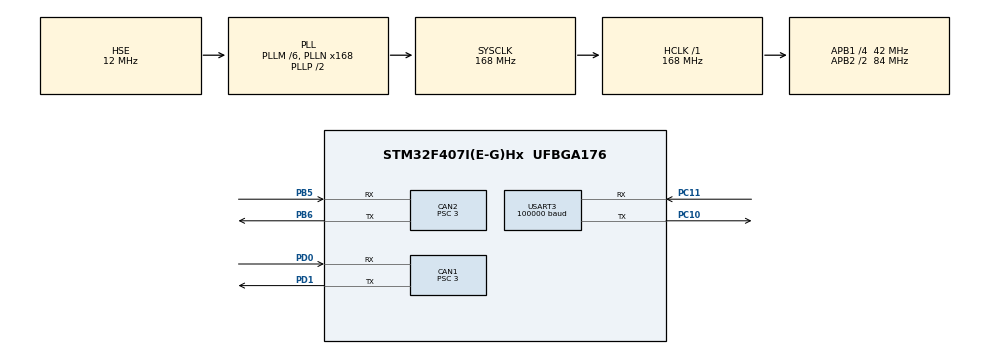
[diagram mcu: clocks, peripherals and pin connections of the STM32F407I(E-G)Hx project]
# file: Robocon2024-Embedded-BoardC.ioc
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CAN1.BS1=CAN_BS1_10TQ
CAN1.BS2=CAN_BS2_3TQ
CAN1.CalculateBaudRate=1000000
CAN1.CalculateTimeBit=1000
CAN1.CalculateTimeQuantum=71.42857142857143
CAN1.Prescaler=3
CAN2.BS1=CAN_BS1_10TQ
CAN2.BS2=CAN_BS2_3TQ
CAN2.CalculateBaudRate=1000000
CAN2.CalculateTimeBit=1000
CAN2.CalculateTimeQuantum=71.42857142857143
CAN2.Prescaler=3
Dma.Request0=USART3_RX
Dma.USART3_RX.0.Direction=DMA_PERIPH_TO_MEMORY
Dma.USART3_RX.0.FIFOMode=DMA_FIFOMODE_DISABLE
Dma.USART3_RX.0.Instance=DMA1_Stream1
Dma.USART3_RX.0.MemDataAlignment=DMA_MDATAALIGN_BYTE
Dma.USART3_RX.0.MemInc=DMA_MINC_ENABLE
Dma.USART3_RX.0.Mode=DMA_NORMAL
Dma.USART3_RX.0.PeriphDataAlignment=DMA_PDATAALIGN_BYTE
Dma.USART3_RX.0.PeriphInc=DMA_PINC_DISABLE
Dma.USART3_RX.0.Priority=DMA_PRIORITY_LOW
FREERTOS.Tasks01=workerTask,8,256,worker_task,As weak,NULL,Static,defaultTaskBuffer,defaultTaskControlBlock
FREERTOS.configENABLE_FPU=1
FREERTOS.configMINIMAL_STACK_SIZE=256
FREERTOS.configRECORD_STACK_HIGH_ADDRESS=1
Mcu.Family=STM32F4
Mcu.Name=STM32F407I(E-G)Hx
Mcu.Package=UFBGA176
NVIC.CAN1_RX0_IRQn=true\:5\:0\:false\:false\:true\:true\:true\:true\:true
NVIC.CAN1_RX1_IRQn=true\:5\:0\:false\:false\:true\:true\:true\:true\:true
NVIC.CAN1_SCE_IRQn=true\:5\:0\:false\:false\:true\:true\:true\:true\:true
NVIC.CAN1_TX_IRQn=true\:5\:0\:false\:false\:true\:true\:true\:true\:true
NVIC.DMA1_Stream1_IRQn=true\:5\:0\:false\:false\:true\:true\:false\:true\:true
NVIC.HASH_RNG_IRQn=true\:5\:0\:false\:false\:true\:true\:true\:true\:true
NVIC.PriorityGroup=NVIC_PRIORITYGROUP_4
NVIC.TIM1_BRK_TIM9_IRQn=true\:5\:0\:false\:false\:true\:true\:true\:false\:true
NVIC.TIM6_DAC_IRQn=true\:0\:0\:true\:false\:true\:false\:false\:true\:true
NVIC.TIM8_BRK_TIM12_IRQn=true\:5\:0\:false\:false\:true\:true\:true\:false\:true
NVIC.TimeBase=TIM6_DAC_IRQn
NVIC.TimeBaseIP=TIM6
NVIC.USART3_IRQn=true\:5\:0\:false\:false\:true\:true\:true\:true\:true
PA13.Mode=Serial_Wire
PA13.Signal=SYS_JTMS-SWDIO
PA14.Mode=Serial_Wire
PA14.Signal=SYS_JTCK-SWCLK
PB5.Mode=CAN_Activate
PB5.Signal=CAN2_RX
PB6.Mode=CAN_Activate
PB6.Signal=CAN2_TX
PC10.Mode=Asynchronous
PC10.Signal=USART3_TX
PC11.Mode=Asynchronous
PC11.Signal=USART3_RX
PD0.Mode=CAN_Activate
PD0.Signal=CAN1_RX
PD1.Mode=CAN_Activate
PD1.Signal=CAN1_TX
PH0-OSC_IN.Mode=HSE-External-Oscillator
PH0-OSC_IN.Signal=RCC_OSC_IN
PH1-OSC_OUT.Mode=HSE-External-Oscillator
PH1-OSC_OUT.Signal=RCC_OSC_OUT
ProjectManager.HeapSize=0x200
ProjectManager.StackSize=0x400
ProjectManager.TargetToolchain=Makefile
RCC.48MHZClocksFreq_Value=48000000
RCC.AHBFreq_Value=168000000
RCC.APB1CLKDivider=RCC_HCLK_DIV4
RCC.APB1Freq_Value=42000000
RCC.APB1TimFreq_Value=84000000
RCC.APB2CLKDivider=RCC_HCLK_DIV2
RCC.APB2Freq_Value=84000000
RCC.APB2TimFreq_Value=168000000
RCC.CortexFreq_Value=168000000
RCC.HCLKFreq_Value=168000000
RCC.HSE_VALUE=12000000
RCC.HSI_VALUE=16000000
RCC.LSE_VALUE=32768
RCC.PLLM=6
RCC.PLLN=168
RCC.PLLQ=7
RCC.PLLSourceVirtual=RCC_PLLSOURCE_HSE
RCC.SYSCLKFreq_VALUE=168000000
RCC.SYSCLKSource=RCC_SYSCLKSOURCE_PLLCLK
RCC.VCOOutputFreq_Value=336000000
TIM12.Channel-Output\ Compare1\ No\ Output=TIM_CHANNEL_1
TIM12.Channel-Output\ Compare2\ No\ Output=TIM_CHANNEL_2
TIM12.Prescaler=83
TIM9.AutoReloadPreload=TIM_AUTORELOAD_PRELOAD_DISABLE
TIM9.Channel-Output\ Compare1\ No\ Output=TIM_CHANNEL_1
TIM9.Channel-Output\ Compare2\ No\ Output=TIM_CHANNEL_2
TIM9.Prescaler=167
USART3.BaudRate=100000
USART3.Mode=MODE_RX
USART3.Parity=PARITY_EVEN
USART3.StopBits=STOPBITS_2
USART3.VirtualMode=VM_ASYNC
USART3.WordLength=WORDLENGTH_9B
VP_CRC_VS_CRC.Mode=CRC_Activate
VP_FREERTOS_VS_CMSIS_V2.Mode=CMSIS_V2
VP_RNG_VS_RNG.Mode=RNG_Activate
VP_SYS_VS_tim6.Mode=TIM6
VP_TIM12_VS_ClockSourceINT.Mode=Internal
VP_TIM12_VS_no_output1.Mode=Output Compare1 No Output
VP_TIM12_VS_no_output2.Mode=Output Compare2 No Output
VP_TIM9_VS_ClockSourceINT.Mode=Internal
VP_TIM9_VS_no_output1.Mode=Output Compare1 No Output
VP_TIM9_VS_no_output2.Mode=Output Compare2 No Output
board=custom

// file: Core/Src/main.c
/* USER CODE BEGIN Header */
/**
  ******************************************************************************
  * @file           : main.c
  * @brief          : Main program body
  ******************************************************************************
  * @attention
  *
  * Copyright (c) 2023 STMicroelectronics.
  * All rights reserved.
  *
  * This software is licensed under terms that can be found in the LICENSE file
  * in the root directory of this software component.
  * If no LICENSE file comes with this software, it is provided AS-IS.
  *
  ******************************************************************************
  */
/* USER CODE END Header */
#include "main.h"
#include "cmsis_os.h"
#include "can.h"
#include "crc.h"
#include "dma.h"
#include "rng.h"
#include "tim.h"
#include "usart.h"
#include "gpio.h"

/* USER CODE BEGIN Includes */
#include "initcall.h"
/* USER CODE END Includes */

void SystemClock_Config(void);
void MX_FREERTOS_Init(void);

int main(void)
{
  /* USER CODE BEGIN 1 */
  Initcall_doPure();
  /* USER CODE END 1 */

  /* MCU Configuration--------------------------------------------------------*/

  /* Reset of all peripherals, Initializes the Flash interface and the Systick. */
  HAL_Init();

  /* Configure the system clock */
  SystemClock_Config();

  /* Initialize all configured peripherals */
  MX_GPIO_Init();
  MX_DMA_Init();
  MX_CAN1_Init();
  MX_CAN2_Init();
  MX_USART3_UART_Init();
  MX_TIM9_Init();
  MX_TIM12_Init();
  MX_CRC_Init();
  MX_RNG_Init();
  /* USER CODE BEGIN 2 */
  Initcall_doDevice();
  /* USER CODE END 2 */

  /* Init scheduler */
  osKernelInitialize();  /* Call init function for freertos objects (in freertos.c) */
  MX_FREERTOS_Init();

  /* Start scheduler */
  osKernelStart();

  /* We should never get here as control is now taken by the scheduler */
  /* Infinite loop */
  while (1)
  {

  }
}

void SystemClock_Config(void)
{
  RCC_OscInitTypeDef RCC_OscInitStruct = {0};
  RCC_ClkInitTypeDef RCC_ClkInitStruct = {0};

  /** Configure the main internal regulator output voltage
  */
  __HAL_RCC_PWR_CLK_ENABLE();
  __HAL_PWR_VOLTAGESCALING_CONFIG(PWR_REGULATOR_VOLTAGE_SCALE1);

  /** Initializes the RCC Oscillators according to the specified parameters
  * in the RCC_OscInitTypeDef structure.
  */
  RCC_OscInitStruct.OscillatorType = RCC_OSCILLATORTYPE_HSE;
  RCC_OscInitStruct.HSEState = RCC_HSE_ON;
  RCC_OscInitStruct.PLL.PLLState = RCC_PLL_ON;
  RCC_OscInitStruct.PLL.PLLSource = RCC_PLLSOURCE_HSE;
  RCC_OscInitStruct.PLL.PLLM = 6;
  RCC_OscInitStruct.PLL.PLLN = 168;
  RCC_OscInitStruct.PLL.PLLP = RCC_PLLP_DIV2;
  RCC_OscInitStruct.PLL.PLLQ = 7;
  if (HAL_RCC_OscConfig(&RCC_OscInitStruct) != HAL_OK)
  {
    Error_Handler();
  }

  /** Initializes the CPU, AHB and APB buses clocks
  */
  RCC_ClkInitStruct.ClockType = RCC_CLOCKTYPE_HCLK|RCC_CLOCKTYPE_SYSCLK
                              |RCC_CLOCKTYPE_PCLK1|RCC_CLOCKTYPE_PCLK2;
  RCC_ClkInitStruct.SYSCLKSource = RCC_SYSCLKSOURCE_PLLCLK;
  RCC_ClkInitStruct.AHBCLKDivider = RCC_SYSCLK_DIV1;
  RCC_ClkInitStruct.APB1CLKDivider = RCC_HCLK_DIV4;
  RCC_ClkInitStruct.APB2CLKDivider = RCC_HCLK_DIV2;

  if (HAL_RCC_ClockConfig(&RCC_ClkInitStruct, FLASH_LATENCY_5) != HAL_OK)
  {
    Error_Handler();
  }
}

void HAL_TIM_PeriodElapsedCallback(TIM_HandleTypeDef *htim)
{
  if (htim->Instance == TIM6) {
    HAL_IncTick();
  }
}

void Error_Handler(void)
{
  __disable_irq();
  while (1)
  {
  }
}

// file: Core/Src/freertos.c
/* USER CODE BEGIN Header */
/**
  ******************************************************************************
  * File Name          : freertos.c
  * Description        : Code for freertos applications
  ******************************************************************************
  * @attention
  *
  * Copyright (c) 2023 STMicroelectronics.
  * All rights reserved.
  *
  * This software is licensed under terms that can be found in the LICENSE file
  * in the root directory of this software component.
  * If no LICENSE file comes with this software, it is provided AS-IS.
  *
  ******************************************************************************
  */
/* USER CODE END Header */

#include "FreeRTOS.h"
#include "task.h"
#include "main.h"
#include "cmsis_os.h"

typedef StaticTask_t osStaticThreadDef_t;

/* Definitions for workerTask */
osThreadId_t workerTaskHandle;
uint32_t defaultTaskBuffer[ 256 ];
osStaticThreadDef_t defaultTaskControlBlock;
const osThreadAttr_t workerTask_attributes = {
  .name = "workerTask",
  .cb_mem = &defaultTaskControlBlock,
  .cb_size = sizeof(defaultTaskControlBlock),
  .stack_mem = &defaultTaskBuffer[0],
  .stack_size = sizeof(defaultTaskBuffer),
  .priority = (osPriority_t) osPriorityLow,
};

void worker_task(void *argument);

void MX_FREERTOS_Init(void); /* (MISRA C 2004 rule 8.1) */

void MX_FREERTOS_Init(void) {

  /* Create the thread(s) */
  /* creation of workerTask */
  workerTaskHandle = osThreadNew(worker_task, NULL, &workerTask_attributes);

}

__weak void worker_task(void *argument)
{
  for(;;)
  {
    osDelay(1);
  }
}
